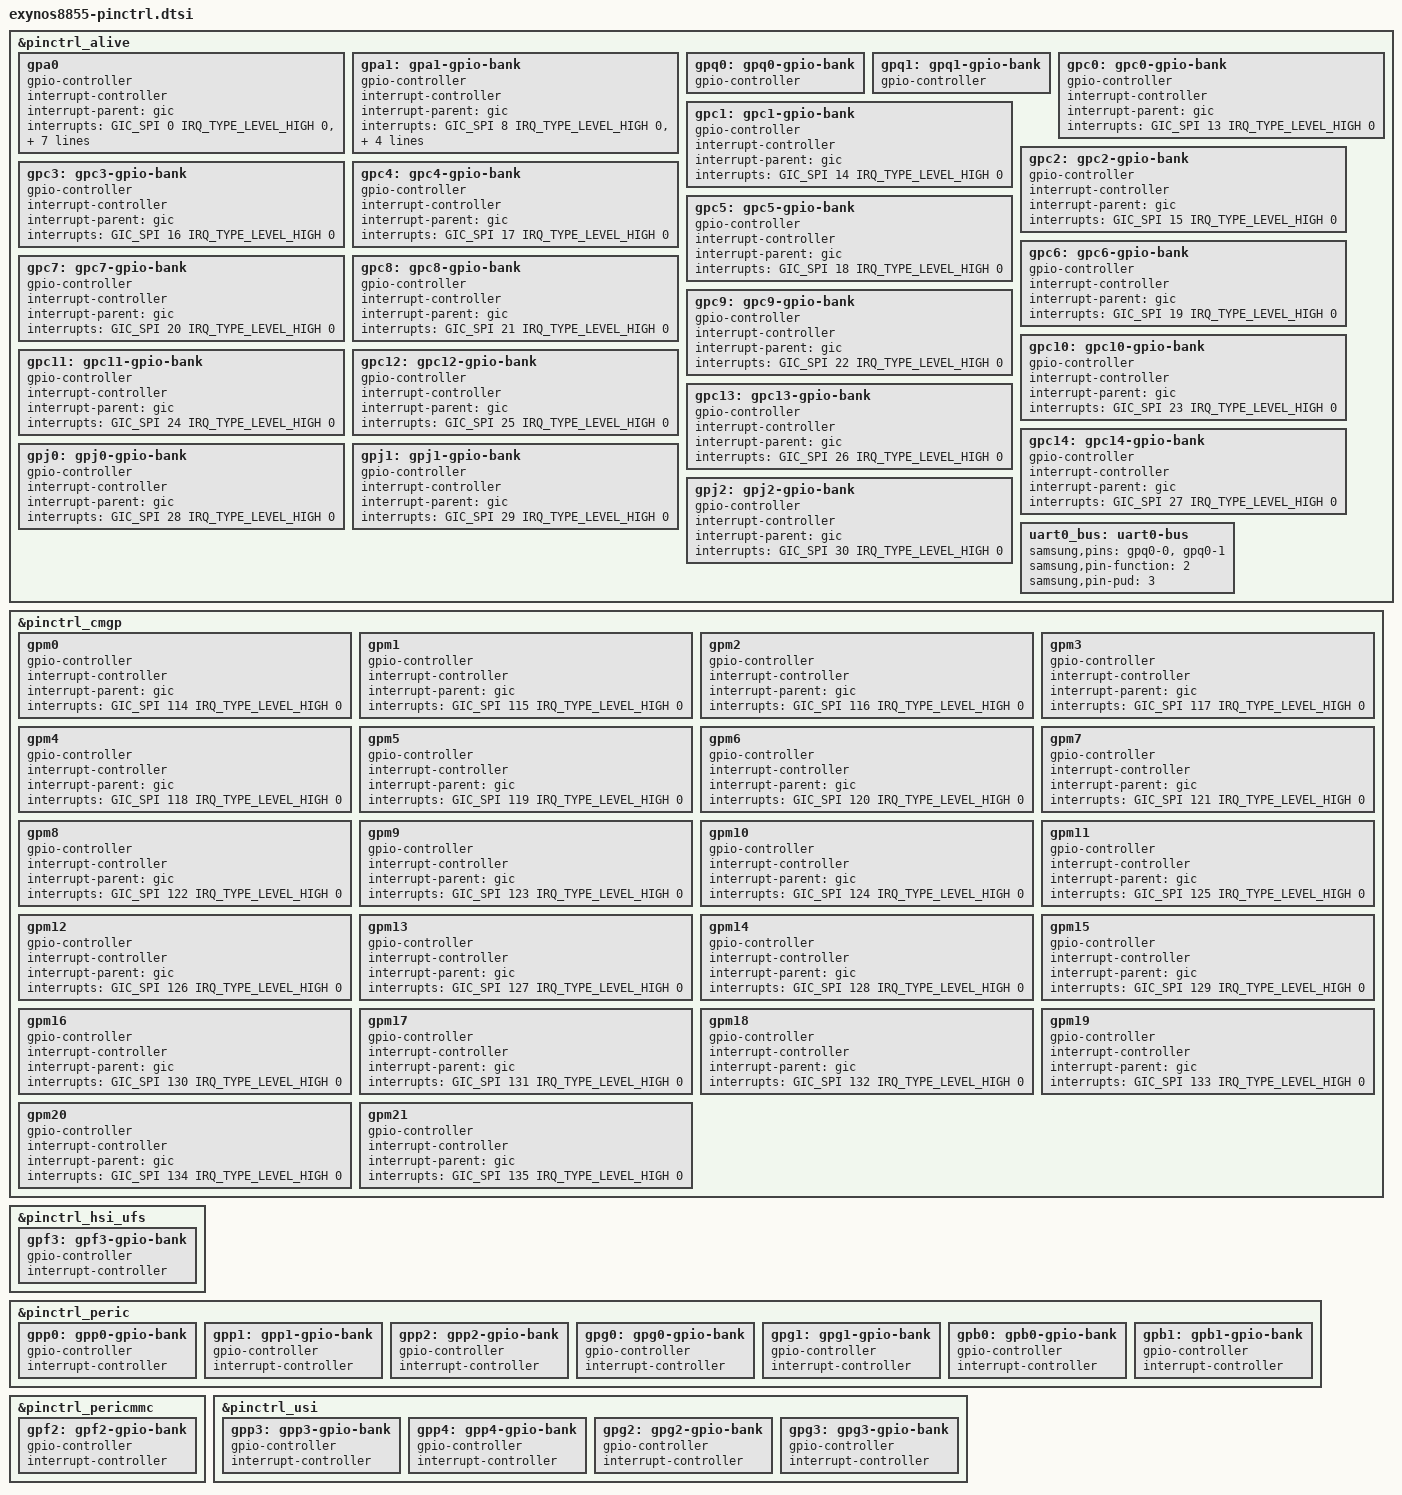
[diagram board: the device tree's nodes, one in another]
// SPDX-License-Identifier: GPL-2.0
/*
 * Samsung's S5E8855 SoC pin-mux and pin-config device tree source
 *
 * Copyright (c) 2023 Samsung Electronics Co., Ltd.
 *		http://www.samsung.com
 *
 * Samsung's S5E8855 SoC pin-mux and pin-config options are listed as device
 * tree nodes are listed in this file.
 *
 * This program is free software; you can redistribute it and/or modify
 * it under the terms of the GNU General Public License version 2 as
 * published by the Free Software Foundation.
 */

#include <dt-bindings/interrupt-controller/arm-gic.h>
#include "exynos-pinctrl.h"

&pinctrl_alive {
	gpa0: gpa0 {
		gpio-controller;
		#gpio-cells = <2>;

		interrupt-controller;
		#interrupt-cells = <2>;
		interrupt-parent = <&gic>;
		interrupts = <GIC_SPI 0 IRQ_TYPE_LEVEL_HIGH 0>,
			     <GIC_SPI 1 IRQ_TYPE_LEVEL_HIGH 0>,
			     <GIC_SPI 2 IRQ_TYPE_LEVEL_HIGH 0>,
			     <GIC_SPI 3 IRQ_TYPE_LEVEL_HIGH 0>,
			     <GIC_SPI 4 IRQ_TYPE_LEVEL_HIGH 0>,
			     <GIC_SPI 5 IRQ_TYPE_LEVEL_HIGH 0>,
			     <GIC_SPI 6 IRQ_TYPE_LEVEL_HIGH 0>,
			     <GIC_SPI 7 IRQ_TYPE_LEVEL_HIGH 0>;
	};

	gpa1: gpa1-gpio-bank {
		gpio-controller;
		#gpio-cells = <2>;

		interrupt-controller;
		#interrupt-cells = <2>;
		interrupt-parent = <&gic>;
		interrupts = <GIC_SPI 8 IRQ_TYPE_LEVEL_HIGH 0>,
			     <GIC_SPI 9 IRQ_TYPE_LEVEL_HIGH 0>,
			     <GIC_SPI 10 IRQ_TYPE_LEVEL_HIGH 0>,
			     <GIC_SPI 11 IRQ_TYPE_LEVEL_HIGH 0>,
			     <GIC_SPI 12 IRQ_TYPE_LEVEL_HIGH 0>;
	};

	gpq0: gpq0-gpio-bank {
		gpio-controller;
		#gpio-cells = <2>;
	};

	gpq1: gpq1-gpio-bank {
		gpio-controller;
		#gpio-cells = <2>;
	};

	gpc0: gpc0-gpio-bank {
		gpio-controller;
		#gpio-cells = <2>;

		interrupt-controller;
		#interrupt-cells = <2>;
		interrupt-parent = <&gic>;
		interrupts = <GIC_SPI 13 IRQ_TYPE_LEVEL_HIGH 0>;
	};

	gpc1: gpc1-gpio-bank {
		gpio-controller;
		#gpio-cells = <2>;

		interrupt-controller;
		#interrupt-cells = <2>;
		interrupt-parent = <&gic>;
		interrupts = <GIC_SPI 14 IRQ_TYPE_LEVEL_HIGH 0>;
	};

	gpc2: gpc2-gpio-bank {
		gpio-controller;
		#gpio-cells = <2>;

		interrupt-controller;
		#interrupt-cells = <2>;
		interrupt-parent = <&gic>;
		interrupts = <GIC_SPI 15 IRQ_TYPE_LEVEL_HIGH 0>;
	};

	gpc3: gpc3-gpio-bank {
		gpio-controller;
		#gpio-cells = <2>;

		interrupt-controller;
		#interrupt-cells = <2>;
		interrupt-parent = <&gic>;
		interrupts = <GIC_SPI 16 IRQ_TYPE_LEVEL_HIGH 0>;
	};

	gpc4: gpc4-gpio-bank {
		gpio-controller;
		#gpio-cells = <2>;

		interrupt-controller;
		#interrupt-cells = <2>;
		interrupt-parent = <&gic>;
		interrupts = <GIC_SPI 17 IRQ_TYPE_LEVEL_HIGH 0>;
	};

	gpc5: gpc5-gpio-bank {
		gpio-controller;
		#gpio-cells = <2>;

		interrupt-controller;
		#interrupt-cells = <2>;
		interrupt-parent = <&gic>;
		interrupts = <GIC_SPI 18 IRQ_TYPE_LEVEL_HIGH 0>;
	};

	gpc6: gpc6-gpio-bank {
		gpio-controller;
		#gpio-cells = <2>;

		interrupt-controller;
		#interrupt-cells = <2>;
		interrupt-parent = <&gic>;
		interrupts = <GIC_SPI 19 IRQ_TYPE_LEVEL_HIGH 0>;
	};

	gpc7: gpc7-gpio-bank {
		gpio-controller;
		#gpio-cells = <2>;

		interrupt-controller;
		#interrupt-cells = <2>;
		interrupt-parent = <&gic>;
		interrupts = <GIC_SPI 20 IRQ_TYPE_LEVEL_HIGH 0>;
	};

	gpc8: gpc8-gpio-bank {
		gpio-controller;
		#gpio-cells = <2>;

		interrupt-controller;
		#interrupt-cells = <2>;
		interrupt-parent = <&gic>;
		interrupts = <GIC_SPI 21 IRQ_TYPE_LEVEL_HIGH 0>;
	};

	gpc9: gpc9-gpio-bank {
		gpio-controller;
		#gpio-cells = <2>;

		interrupt-controller;
		#interrupt-cells = <2>;
		interrupt-parent = <&gic>;
		interrupts = <GIC_SPI 22 IRQ_TYPE_LEVEL_HIGH 0>;
	};

	gpc10: gpc10-gpio-bank {
		gpio-controller;
		#gpio-cells = <2>;

		interrupt-controller;
		#interrupt-cells = <2>;
		interrupt-parent = <&gic>;
		interrupts = <GIC_SPI 23 IRQ_TYPE_LEVEL_HIGH 0>;
	};

	gpc11: gpc11-gpio-bank {
		gpio-controller;
		#gpio-cells = <2>;

		interrupt-controller;
		#interrupt-cells = <2>;
		interrupt-parent = <&gic>;
		interrupts = <GIC_SPI 24 IRQ_TYPE_LEVEL_HIGH 0>;
	};

	gpc12: gpc12-gpio-bank {
		gpio-controller;
		#gpio-cells = <2>;

		interrupt-controller;
		#interrupt-cells = <2>;
		interrupt-parent = <&gic>;
		interrupts = <GIC_SPI 25 IRQ_TYPE_LEVEL_HIGH 0>;
	};

	gpc13: gpc13-gpio-bank {
		gpio-controller;
		#gpio-cells = <2>;

		interrupt-controller;
		#interrupt-cells = <2>;
		interrupt-parent = <&gic>;
		interrupts = <GIC_SPI 26 IRQ_TYPE_LEVEL_HIGH 0>;
	};

	gpc14: gpc14-gpio-bank {
		gpio-controller;
		#gpio-cells = <2>;

		interrupt-controller;
		#interrupt-cells = <2>;
		interrupt-parent = <&gic>;
		interrupts = <GIC_SPI 27 IRQ_TYPE_LEVEL_HIGH 0>;
	};

	gpj0: gpj0-gpio-bank {
		gpio-controller;
		#gpio-cells = <2>;

		interrupt-controller;
		#interrupt-cells = <2>;
		interrupt-parent = <&gic>;
		interrupts = <GIC_SPI 28 IRQ_TYPE_LEVEL_HIGH 0>;
	};

	gpj1: gpj1-gpio-bank {
		gpio-controller;
		#gpio-cells = <2>;

		interrupt-controller;
		#interrupt-cells = <2>;
		interrupt-parent = <&gic>;
		interrupts = <GIC_SPI 29 IRQ_TYPE_LEVEL_HIGH 0>;
	};

	gpj2: gpj2-gpio-bank {
		gpio-controller;
		#gpio-cells = <2>;

		interrupt-controller;
		#interrupt-cells = <2>;
		interrupt-parent = <&gic>;
		interrupts = <GIC_SPI 30 IRQ_TYPE_LEVEL_HIGH 0>;
	};

	uart0_bus: uart0-bus {
		samsung,pins = "gpq0-0", "gpq0-1";
		samsung,pin-function = <2>;
		samsung,pin-pud = <3>;
	};

};

&pinctrl_cmgp {
	gpm0: gpm0 {
		gpio-controller;
		#gpio-cells = <2>;

		interrupt-controller;
		#interrupt-cells = <2>;
		interrupt-parent = <&gic>;
		interrupts = <GIC_SPI 114 IRQ_TYPE_LEVEL_HIGH 0>;
	};

	gpm1: gpm1 {
		gpio-controller;
		#gpio-cells = <2>;

		interrupt-controller;
		#interrupt-cells = <2>;
		interrupt-parent = <&gic>;
		interrupts = <GIC_SPI 115 IRQ_TYPE_LEVEL_HIGH 0>;
	};

	gpm2: gpm2 {
		gpio-controller;
		#gpio-cells = <2>;

		interrupt-controller;
		#interrupt-cells = <2>;
		interrupt-parent = <&gic>;
		interrupts = <GIC_SPI 116 IRQ_TYPE_LEVEL_HIGH 0>;
	};

	gpm3: gpm3 {
		gpio-controller;
		#gpio-cells = <2>;

		interrupt-controller;
		#interrupt-cells = <2>;
		interrupt-parent = <&gic>;
		interrupts = <GIC_SPI 117 IRQ_TYPE_LEVEL_HIGH 0>;
	};

	gpm4: gpm4 {
		gpio-controller;
		#gpio-cells = <2>;

		interrupt-controller;
		#interrupt-cells = <2>;
		interrupt-parent = <&gic>;
		interrupts = <GIC_SPI 118 IRQ_TYPE_LEVEL_HIGH 0>;
	};

	gpm5: gpm5 {
		gpio-controller;
		#gpio-cells = <2>;

		interrupt-controller;
		#interrupt-cells = <2>;
		interrupt-parent = <&gic>;
		interrupts = <GIC_SPI 119 IRQ_TYPE_LEVEL_HIGH 0>;
	};

	gpm6: gpm6 {
		gpio-controller;
		#gpio-cells = <2>;

		interrupt-controller;
		#interrupt-cells = <2>;
		interrupt-parent = <&gic>;
		interrupts = <GIC_SPI 120 IRQ_TYPE_LEVEL_HIGH 0>;
	};

	gpm7: gpm7 {
		gpio-controller;
		#gpio-cells = <2>;

		interrupt-controller;
		#interrupt-cells = <2>;
		interrupt-parent = <&gic>;
		interrupts = <GIC_SPI 121 IRQ_TYPE_LEVEL_HIGH 0>;
	};

	gpm8: gpm8 {
		gpio-controller;
		#gpio-cells = <2>;

		interrupt-controller;
		#interrupt-cells = <2>;
		interrupt-parent = <&gic>;
		interrupts = <GIC_SPI 122 IRQ_TYPE_LEVEL_HIGH 0>;
	};

	gpm9: gpm9 {
		gpio-controller;
		#gpio-cells = <2>;

		interrupt-controller;
		#interrupt-cells = <2>;
		interrupt-parent = <&gic>;
		interrupts = <GIC_SPI 123 IRQ_TYPE_LEVEL_HIGH 0>;
	};

	gpm10: gpm10 {
		gpio-controller;
		#gpio-cells = <2>;

		interrupt-controller;
		#interrupt-cells = <2>;
		interrupt-parent = <&gic>;
		interrupts = <GIC_SPI 124 IRQ_TYPE_LEVEL_HIGH 0>;
	};

	gpm11: gpm11 {
		gpio-controller;
		#gpio-cells = <2>;

		interrupt-controller;
		#interrupt-cells = <2>;
		interrupt-parent = <&gic>;
		interrupts = <GIC_SPI 125 IRQ_TYPE_LEVEL_HIGH 0>;
	};

	gpm12: gpm12 {
		gpio-controller;
		#gpio-cells = <2>;

		interrupt-controller;
		#interrupt-cells = <2>;
		interrupt-parent = <&gic>;
		interrupts = <GIC_SPI 126 IRQ_TYPE_LEVEL_HIGH 0>;
	};

	gpm13: gpm13 {
		gpio-controller;
		#gpio-cells = <2>;

		interrupt-controller;
		#interrupt-cells = <2>;
		interrupt-parent = <&gic>;
		interrupts = <GIC_SPI 127 IRQ_TYPE_LEVEL_HIGH 0>;
	};

	gpm14: gpm14 {
		gpio-controller;
		#gpio-cells = <2>;

		interrupt-controller;
		#interrupt-cells = <2>;
		interrupt-parent = <&gic>;
		interrupts = <GIC_SPI 128 IRQ_TYPE_LEVEL_HIGH 0>;
	};

	gpm15: gpm15 {
		gpio-controller;
		#gpio-cells = <2>;

		interrupt-controller;
		#interrupt-cells = <2>;
		interrupt-parent = <&gic>;
		interrupts = <GIC_SPI 129 IRQ_TYPE_LEVEL_HIGH 0>;
	};

	gpm16: gpm16 {
		gpio-controller;
		#gpio-cells = <2>;

		interrupt-controller;
		#interrupt-cells = <2>;
		interrupt-parent = <&gic>;
		interrupts = <GIC_SPI 130 IRQ_TYPE_LEVEL_HIGH 0>;
	};

	gpm17: gpm17 {
		gpio-controller;
		#gpio-cells = <2>;

		interrupt-controller;
		#interrupt-cells = <2>;
		interrupt-parent = <&gic>;
		interrupts = <GIC_SPI 131 IRQ_TYPE_LEVEL_HIGH 0>;
	};

	gpm18: gpm18 {
		gpio-controller;
		#gpio-cells = <2>;

		interrupt-controller;
		#interrupt-cells = <2>;
		interrupt-parent = <&gic>;
		interrupts = <GIC_SPI 132 IRQ_TYPE_LEVEL_HIGH 0>;
	};

	gpm19: gpm19 {
		gpio-controller;
		#gpio-cells = <2>;

		interrupt-controller;
		#interrupt-cells = <2>;
		interrupt-parent = <&gic>;
		interrupts = <GIC_SPI 133 IRQ_TYPE_LEVEL_HIGH 0>;
	};

	gpm20: gpm20 {
		gpio-controller;
		#gpio-cells = <2>;

		interrupt-controller;
		#interrupt-cells = <2>;
		interrupt-parent = <&gic>;
		interrupts = <GIC_SPI 134 IRQ_TYPE_LEVEL_HIGH 0>;
	};

	gpm21: gpm21 {
		gpio-controller;
		#gpio-cells = <2>;

		interrupt-controller;
		#interrupt-cells = <2>;
		interrupt-parent = <&gic>;
		interrupts = <GIC_SPI 135 IRQ_TYPE_LEVEL_HIGH 0>;
	};
};

&pinctrl_hsi_ufs {
	gpf3: gpf3-gpio-bank{
		gpio-controller;
		#gpio-cells = <2>;

		interrupt-controller;
		#interrupt-cells = <2>;
	};
};

&pinctrl_peric {
	gpp0: gpp0-gpio-bank {
		gpio-controller;
		#gpio-cells = <2>;

		interrupt-controller;
		#interrupt-cells = <2>;
	};

	gpp1: gpp1-gpio-bank {
		gpio-controller;
		#gpio-cells = <2>;

		interrupt-controller;
		#interrupt-cells = <2>;
	};

	gpp2: gpp2-gpio-bank {
		gpio-controller;
		#gpio-cells = <2>;

		interrupt-controller;
		#interrupt-cells = <2>;
	};

	gpg0: gpg0-gpio-bank {
		gpio-controller;
		#gpio-cells = <2>;

		interrupt-controller;
		#interrupt-cells = <2>;
	};

	gpg1: gpg1-gpio-bank {
		gpio-controller;
		#gpio-cells = <2>;

		interrupt-controller;
		#interrupt-cells = <2>;
	};

	gpb0: gpb0-gpio-bank {
		gpio-controller;
		#gpio-cells = <2>;

		interrupt-controller;
		#interrupt-cells = <2>;
	};

	gpb1: gpb1-gpio-bank {
		gpio-controller;
		#gpio-cells = <2>;

		interrupt-controller;
		#interrupt-cells = <2>;
	};
};

&pinctrl_pericmmc {
	gpf2: gpf2-gpio-bank {
		gpio-controller;
		#gpio-cells = <2>;

		interrupt-controller;
		#interrupt-cells = <2>;
	};
};

&pinctrl_usi {
	gpp3: gpp3-gpio-bank {
		gpio-controller;
		#gpio-cells = <2>;

		interrupt-controller;
		#interrupt-cells = <2>;
	};

	gpp4: gpp4-gpio-bank {
		gpio-controller;
		#gpio-cells = <2>;

		interrupt-controller;
		#interrupt-cells = <2>;
	};

	gpg2: gpg2-gpio-bank {
		gpio-controller;
		#gpio-cells = <2>;

		interrupt-controller;
		#interrupt-cells = <2>;
	};

	gpg3: gpg3-gpio-bank {
		gpio-controller;
		#gpio-cells = <2>;

		interrupt-controller;
		#interrupt-cells = <2>;
	};
};
